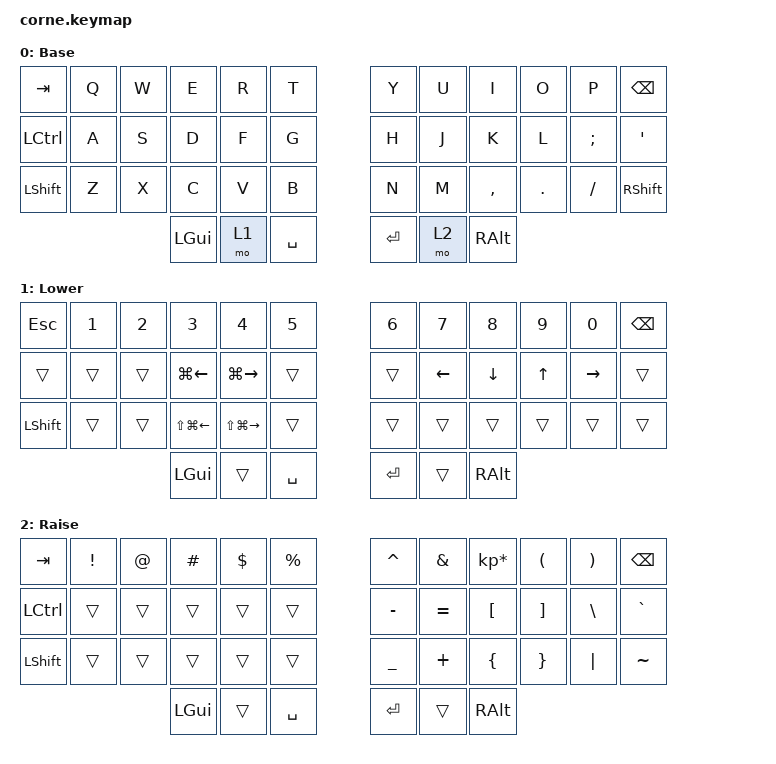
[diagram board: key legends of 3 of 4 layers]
/*
 * Copyright (c) 2020 The ZMK Contributors
 *
 * SPDX-License-Identifier: MIT
 */

#include <behaviors.dtsi>
#include <dt-bindings/zmk/keys.h>
#include <dt-bindings/zmk/bt.h>

/ {
        conditional_layers {
                compatible = "zmk,conditional-layers";
                adjust {
                        if-layers = <1 2>;
                        then-layer = <3>;
                };
        };

        keymap {
                compatible = "zmk,keymap";

                default_layer {
// -----------------------------------------------------------------------------------------
// |  TAB |  Q  |  W  |  E  |  R  |  T  |   |  Y  |  U   |  I  |  O  |  P  | BKSP |
// | CTRL |  A  |  S  |  D  |  F  |  G  |   |  H  |  J   |  K  |  L  |  ;  |  '   |
// | SHFT |  Z  |  X  |  C  |  V  |  B  |   |  N  |  M   |  ,  |  .  |  /  | SHFT |
//                    | GUI | LWR | SPC |   | ENT | RSE  | ALT |
                        display-name = "Base";
                        bindings = <
   &kp TAB   &kp Q &kp W &kp E &kp R &kp T   &kp Y &kp U  &kp I     &kp O   &kp P    &kp BSPC
   &kp LCTRL &kp A &kp S &kp D &kp F &kp G   &kp H &kp J  &kp K     &kp L   &kp SEMI &kp SQT
   &kp LSHFT &kp Z &kp X &kp C &kp V &kp B   &kp N &kp M  &kp COMMA &kp DOT &kp FSLH &kp RSHFT
                  &kp LGUI &mo 1 &kp SPACE   &kp RET &mo 2 &kp RALT
                        >;
                };
                lower_layer {
// -----------------------------------------------------------------------------------------
// | ESC  |  1  |  2  |  3  |  4  |  5  |   |  6  |  7  |  8  |  9  |  0  | BKSP |
// |      |     |     | LG(L)| LG(R)|     |   |     | LFT | DWN |  UP | RGT |      |
// | SHFT |     |     | LS(LG(L))| LS(LG(R))|   |     |     |     |     |     |      |
//                    | GUI |     | SPC |   | ENT |     | ALT |
                        display-name = "Lower";
                        bindings = <
   &kp ESC    &kp N1       &kp N2       &kp N3       &kp N4       &kp N5         &kp N6   &kp N7   &kp N8 &kp N9    &kp N0 &kp BSPC
   &trans     &trans       &trans       &kp LG(LEFT) &kp LG(RIGHT) &trans         &trans   &kp LEFT &kp DOWN &kp UP &kp RIGHT &trans
   &kp LSHFT  &trans       &trans       &kp LS(LG(LEFT)) &kp LS(LG(RIGHT)) &trans         &trans   &trans   &trans &trans    &trans &trans
                          	        &kp LGUI     &trans       &kp SPACE      &kp RET  &trans   &kp RALT
                        >;
                };

                raise_layer {
// -----------------------------------------------------------------------------------------
// |  TAB |  !  |  @  |  #  |  $  |  %  |   |  ^  |  &  |  *  |  (  |  )  | BKSP |
// | CTRL |     |     |     |     |     |   |  -  |  =  |  [  |  ]  |  \  |  `   |
// | SHFT |     |     |     |     |     |   |  _  |  +  |  {  |  }  | "|" |  ~   |
//                    | GUI |     | SPC |   | ENT |     | ALT |
                        display-name = "Raise";
                        bindings = <
   &kp  TAB  &kp EXCL &kp AT &kp HASH &kp DLLR &kp PRCNT   &kp CARET &kp AMPS  &kp KP_MULTIPLY &kp LPAR &kp RPAR &kp BSPC
   &kp LCTRL &trans   &trans &trans   &trans   &trans      &kp MINUS &kp EQUAL &kp LBKT        &kp RBKT &kp BSLH &kp GRAVE
   &kp LSHFT &trans   &trans &trans   &trans   &trans      &kp UNDER &kp PLUS  &kp LBRC        &kp RBRC &kp PIPE &kp TILDE
                    	     &kp LGUI &trans   &kp SPACE   &kp RET   &trans    &kp RALT
                        >;
                };

                adjust_layer {
// -----------------------------------------------------------------------------------------
// | RESET| F1  |  F2 |  F3 |  F4 |  F5 |   |  F6 |  F7 |  F8 |  F9 | F10 | F11  |
// |      |     |     | LS(LG(3))| LS(LG(4))| LS(LG(5))|   |     |     |     |     |     |      |
// |      |     |     |     |     |     |   |     |     |     |     |     |      |
//                    | GUI |     | SPC |   | ENT |     | ALT |
                        display-name = "Adjust";
                        bindings = <
   &sys_reset &kp F1 &kp F2 &kp F3 &kp F4 &kp F5   &kp F6 &kp F7 &kp F8 &kp F9 &kp F10 &kp F11
   &trans    &trans &trans &kp LS(LG(N3)) &kp LS(LG(N4)) &kp LS(LG(N5)) &trans   &trans &trans &trans &trans &trans  &trans
   &trans    &trans &trans &trans &trans &trans   &trans &trans &trans &trans &trans  &trans
                  &kp LGUI &trans &kp SPACE   &kp RET &trans &kp RALT
                        >;
                };

                extra_2 {
                        status = "reserved";
                };

                extra_3 {
                        status = "reserved";
                };
        };
};
